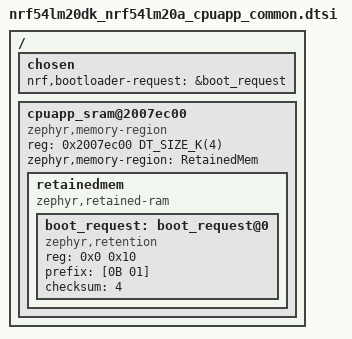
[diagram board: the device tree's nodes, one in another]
/*
 * Copyright (c) 2025 Nordic Semiconductor ASA
 *
 * SPDX-License-Identifier: LicenseRef-Nordic-5-Clause
 */



/ {
	chosen {
		nrf,bootloader-request = &boot_request;
	};
};

/ {
	cpuapp_sram@2007ec00 {
		compatible = "zephyr,memory-region", "mmio-sram";
		reg = <0x2007ec00 DT_SIZE_K(4)>;
		zephyr,memory-region = "RetainedMem";
		status = "okay";
		retainedmem {
			compatible = "zephyr,retained-ram";
			status = "okay";
			#address-cells = <1>;
			#size-cells = <1>;

			boot_request: boot_request@0 {
				compatible = "zephyr,retention";
				status = "okay";
				reg = <0x0 0x10>;
				prefix = [0B 01];
				checksum = <4>;
			};
		};
	};
};
